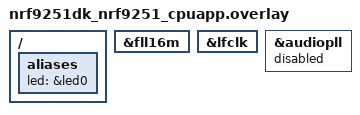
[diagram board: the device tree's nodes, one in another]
/*
 * Copyright (c) 2026 Nordic Semiconductor ASA
 *
 * SPDX-License-Identifier: LicenseRef-Nordic-5-Clause
 */

/ {
	aliases {
		led = &led0;
	};
};

&fll16m {
	status = "okay";
};

&lfclk {
	status = "okay";
};

tst_auxpll: &audiopll {
	status = "disabled";
};
